# MSS_VIM register map
Vendor: Texas Instruments
Peripheral module from a debugger description file (folder awr29xx).
Registers are 32-bit, access per field, no defined reset value unless marked. A register's access mark holds for its fields unless they carry their own. Offsets are as the file gives them; lines under a group give offsets from that group; [hi:lo] are bit positions; {n}, {i} and the like mark numbered series; 'fields as' and 'values as' point back to an identical list; <NAME> marks a mode.

## MSS_VIM
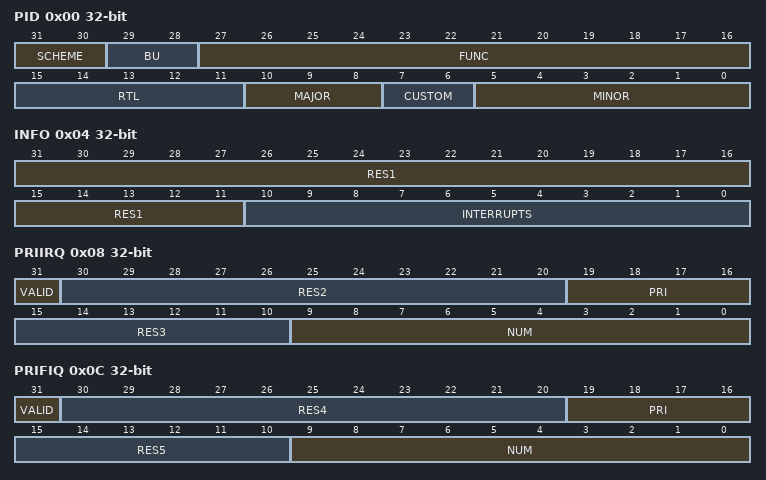
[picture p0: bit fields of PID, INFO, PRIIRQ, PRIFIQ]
0x00 PID ro — The Revision Register contains the major and minor revisions for the module.
  [31:30] SCHEME — PID register scheme
  [29:28] BU — Business Unit: 10 = Processors
  [27:16] FUNC — Module ID
  [15:11] RTL — RTL revision. Will vary depending on release.
  [10:8] MAJOR — Major revision
  [7:6] CUSTOM
  [5:0] MINOR — Minor revision
0x04 INFO ro — The Info Register gives the configuration Inforrmation of this VIM.
  [31:11] RES1 — RESERVE FIELD
  [10:0] INTERRUPTS — Total number of Interrupts
0x08 PRIIRQ ro — The Prioritized IRQ Register shows the number of the highest priority pending IRQ.
  [31] VALID — Indicates that the num field is valid.
  [30:20] RES2 — RESERVE FIELD
  [19:16] PRI — Priority of the highest priority pending IRQ. valid only if the valid flag is set.
  [15:10] RES3 — RESERVE FIELD
  [9:0] NUM — Number of the highest priority pending IRQ. valid only if the valid flag is set.
0x0C PRIFIQ ro — The Prioritized FIQ Register shows the number of the highest priority pending FIQ.
  [31] VALID — Indicates that the num field is valid.
  [30:20] RES4 — RESERVE FIELD
  [19:16] PRI — Priority of the highest priority pending FIQ. valid only if the valid flag is set.
  [15:10] RES5 — RESERVE FIELD
  [9:0] NUM — Number of the highest priority pending FIQ. valid only if the valid flag is set.
0x10 IRQGSTS ro — The IRQ Group Status Register indicates which groups have pending IRQ interrupts.
  [31:0] STS — Indicates that the num field is valid.
0x14 FIQGSTS ro — The FIQ Group Status Register indicates which groups have pending FIQ interrupts.
  [31:0] STS — Indicates that the num field is valid.
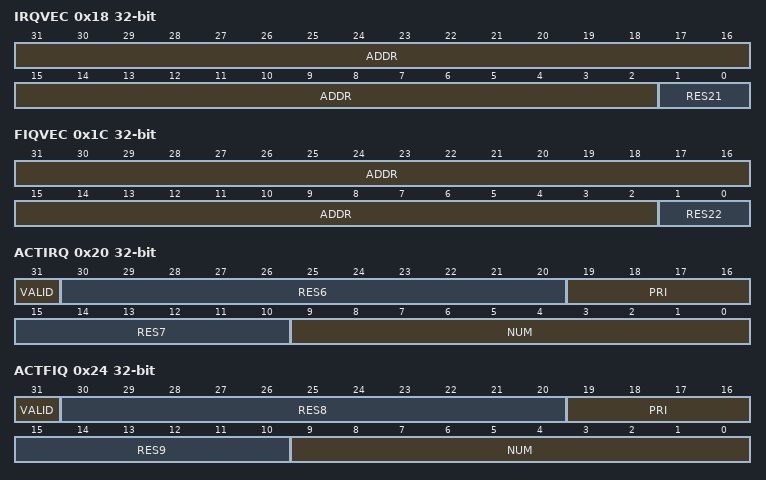
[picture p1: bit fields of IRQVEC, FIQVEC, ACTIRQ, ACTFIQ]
0x18 IRQVEC — The IRQ Vector Address Register contains the 32-bit address of the interrupt vector for the current pendind IRQ.
  [31:2] ADDR rw — Upper 30 bits of the 32-bit vector address. Only valid if the Prioritized IRQ Register valid flag is true.
  [1:0] RES21 ro — RESERVE FIELD
0x1C FIQVEC — The FIQ Vector Address Register contains the 32-bit address of the interrupt vector for the current pendind FIQ.
  [31:2] ADDR rw — Upper 30 bits of the 32-bit vector address. Only valid if the Prioritized FIQ Register valid flag is true.
  [1:0] RES22 ro — RESERVE FIELD
0x20 ACTIRQ ro — The Active IRQ Register shows the number of the currently active IRQ.
  [31] VALID — Indicates that the num field is valid. Set when the IRQ Vector Address Register is read and cleared whenever the IRQ Vector Address Register is written.
  [30:20] RES6 — RESERVE FIELD
  [19:16] PRI — Priority of the highest priority pending IRQ. valid only if the valid flag is set.
  [15:10] RES7 — RESERVE FIELD
  [9:0] NUM — Number of the currently active IRQ. Loaded from teh Prioritized IRQ Register whenever the IRQ Vector Address is read. Valid only if the valid flag is set.
0x24 ACTFIQ ro — The Active FIQ Register shows the number of the currently active FIQ.
  [31] VALID — Indicates that the num field is valid. Set when the FIQ Vector Address Register is read and cleared whenever the FIQ Vector Address Register is written.
  [30:20] RES8 — RESERVE FIELD
  [19:16] PRI — Priority of the highest priority pending IRQ. valid only if the valid flag is set.
  [15:10] RES9 — RESERVE FIELD
  [9:0] NUM — Number of the currently active FIQ. Loaded from teh Prioritized FIQ Register whenever the FIQ Vector Address is read. Valid only if the valid flag is set.
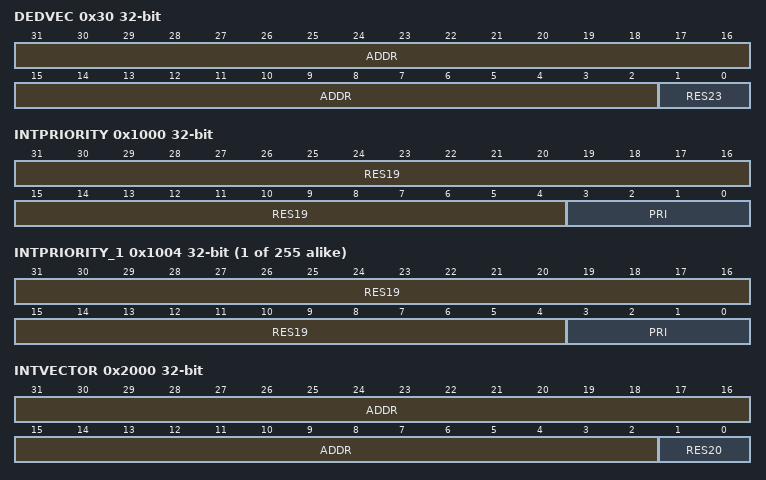
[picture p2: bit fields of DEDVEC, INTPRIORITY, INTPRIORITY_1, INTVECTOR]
0x30 DEDVEC — The DED Vector Address contains a default vector address for when an uncorrectable error is detected for an active IRQ or FIQ.
  [31:2] ADDR rw — Upper 30 bits of the 32-bit vector address.
  [1:0] RES23 ro — RESERVE FIELD
0x400 RAW rw — Group M Interrupt Raw Status/Set Register (M is 0 to 7) h400 + M x h20 + h00
  [31:0] STS — This is the raw status of the events in Group M Each bit corresponds to event Q where Q = Mx32+Bit Read 0 Inactive Read 1 Active/Pending Write 0 No effect Write 1 Set to Interrupt Raw Status
0x404 STS rw — Group M Interrupt Enabled Status/Clear Register (M is 0 to 7) h400 + M x h20 + h04
  [31:0] MASK — This is the masked status of the events in Group M Each bit corresponds to event Q where Q = Mx32+Bit Read 0 Inactive or Disabled Read 1 Active/Pending and Enabled Write 0 No effect Write 1 Clear Interrupt Raw Status
0x408 INTR_EN_SET rw — Group M Interrupt Enabled Set Register (M is 0 to 7) h400 + M x h20 + h08
  [31:0] MASK — This field is used to enable the mask of events in Group M Each bit corresponds to event Q where Q = Mx32+Bit Read 0 Disabled Read 1 Enabled Write 0 No effect Write 1 Set Enable
0x40C INTER_EN_CLR rw — Group M Interrupt Enabled Clear Register (M is 0 to 7) h400 + M x h20 + h0C
  [31:0] MASK — This field is used to disable the mask of events in Group M Each bit corresponds to event Q where Q = Mx32+Bit Read 0 Disabled Read 1 Enabled Write 0 No effect Write 1 Clear Enable
0x410 IRQSTS rw — Group M Interrupt IRQ Enabled Status/Clear Register (M is 0 to 7) h400 + M x h20 + h10
  [31:0] MASK — This is the masked status of the events in group M that are mapped to IRQ Each bit corresponds to event Q where Q = Mx32+Bit Read 0 Inactive, Disabled, or not an IRQ Read 1 Active/Pending, Enabled, and IRQ Write 0 No effect Write 1 Clear Interrupt Raw Status (if IRQ)
0x414 FIQSTS rw — Group M Interrupt FIQ Enabled Status/Clear Register (M is 0 to 7) h400 + M x h20 + h14
  [31:0] MASK — This is the masked status of the events in group M that are mapped to FIQ Each bit corresponds to event Q where Q = Mx32+Bit Read 0 Inactive, Disabled, or not an FIQ Read 1 Active/Pending, Enabled, and FIQ Write 0 No effect Write 1 Clear Interrupt Raw Status (if FIQ)
0x418 INTMAP rw — Group M Interrupt Map Register (M is 0 to 7) h400 + M x h20 + h18
  [31:0] MASK — This field is used to indicate which interrupt the corresponding event influences (if enabled) for event group M. Each bit corresponds to event Q where Q = Mx32+Bit 0 IRQ Interrupt (default) 1 FIQ Interrupt
0x41C INTTYPE rw — Group M Type Map Register (M is 0 to 7) h400 + M x h20 + 0x1C
  [31:0] VAL — This field is used to indicate whether the source of an interrupt is a level (default) or a pulse for event group M. This is informational so that an ISR may query this register and know whether it has to clear a pulse event or a level event (see 3.4 Interrupt Handling). The value has no effect on how the VIM hardware functions. The input interrupts are agnostic as to whether they are pulse or level. Each bit corresponds to event Q where Q = Mx32+Bit 0 Level (default) 1 Pulse
{0x400+0x20*i} RAW_{i} rw (i=1..7) — Group M Interrupt Raw Status/Set Register (M is 0 to 7) h400 + M x h20 + h00
  fields as RAW
{0x404+0x20*i} STS_{i} rw (i=1..7) — Group M Interrupt Enabled Status/Clear Register (M is 0 to 7) h400 + M x h20 + h04
  fields as STS
{0x408+0x20*i} INTR_EN_SET_{i} rw (i=1..7) — Group M Interrupt Enabled Set Register (M is 0 to 7) h400 + M x h20 + h08
  fields as INTR_EN_SET
{0x40C+0x20*i} INTER_EN_CLR_{i} rw (i=1..7) — Group M Interrupt Enabled Clear Register (M is 0 to 7) h400 + M x h20 + h0C
  fields as INTER_EN_CLR
{0x410+0x20*i} IRQSTS_{i} rw (i=1..7) — Group M Interrupt IRQ Enabled Status/Clear Register (M is 0 to 7) h400 + M x h20 + h10
  fields as IRQSTS
{0x414+0x20*i} FIQSTS_{i} rw (i=1..7) — Group M Interrupt FIQ Enabled Status/Clear Register (M is 0 to 7) h400 + M x h20 + h14
  fields as FIQSTS
{0x418+0x20*i} INTMAP_{i} rw (i=1..7) — Group M Interrupt Map Register (M is 0 to 7) h400 + M x h20 + h18
  fields as INTMAP
{0x41C+0x20*i} INTTYPE_{i} rw (i=1..7) — Group M Type Map Register (M is 0 to 7) h400 + M x h20 + 0x1C
  fields as INTTYPE
0x1000 INTPRIORITY — Interrupt Q Priority Register (Q is 0 to 255 , Q= M+1 x 32) h1000 + Q x h4
  [31:4] RES19 ro — RESERVE FIELD
  [3:0] PRI rw — This is the priority for interrupt Q. If two interrupts have the same priority, then whichever interrupt has the lower number Q wins arbitration 0 Highest Priority 15 Lowest Priority (Default)
{0x1000+4i} INTPRIORITY_{i} (i=1..255) — Interrupt Q Priority Register (Q is 0 to 255 , Q= M+1 x 32) h1000 + Q x h{i+4}
  fields as INTPRIORITY
0x2000 INTVECTOR — Interrupt Q Vector Register (Q is 0 to 255 , Q= M+1 x 32) h2000 + Q x h4
  [31:2] ADDR rw — This is the 32-bit Vector Address associated with interrupt Q. It is the address that will be reflected in the IRQ Vector Address (Base Address + 0x18) or FIQ Vector Address (Base Address + 0x1C) and the VECADDR pin when interrupt Q is the active interrupt. Internally, these values are kept in a RAM. The FIQ and IRQ state machines have priority access to this RAM. Writes to this register will be piped internally, but further writes to the MMR interface may be stalled until this write has a chance to complete in the RAM. The new Vector Address will not take effect until this write completes to the RAM. In order to tell if this write has completed, software may read this register back. That read will not be able to complete unless the write has landed. Reads to this register will stall the MMR interface until the read is able to be completed at the RAM.
  [1:0] RES20 ro — Reserved. Read as 0. The lower 2 bits of the 32-bit vector address are always 0. Vector addresses must be 32-bit aligned.
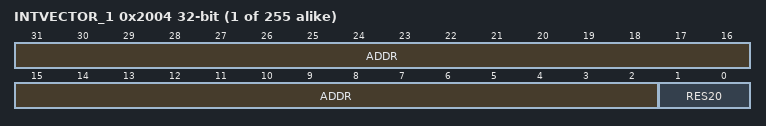
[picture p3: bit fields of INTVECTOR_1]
{0x2000+4i} INTVECTOR_{i} (i=1..255) — Interrupt Q Vector Register (Q is 0 to 255 , Q= M+1 x 32) h2000 + Q x h{i+4}
  fields as INTVECTOR
